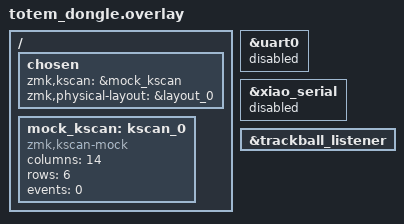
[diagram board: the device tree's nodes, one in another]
#include "totem.dtsi"
#include "totem-layouts.dtsi"
#include "trackmouse.dtsi"
/ {
    chosen {
        zmk,kscan = &mock_kscan;
        zmk,physical-layout = &layout_0;
    };

    mock_kscan: kscan_0 {
        compatible = "zmk,kscan-mock";
        columns = <14>;
        rows = <6>;
        events = <0>;
    };
};

&uart0 {
    status = "disabled";
};

&xiao_serial {
    status = "disabled";
};

&trackball_listener{
        status = "okay";
};

